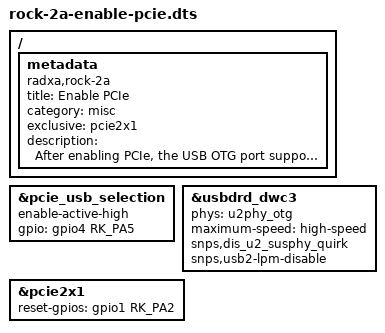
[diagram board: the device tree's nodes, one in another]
/dts-v1/;
/plugin/;

#include <dt-bindings/gpio/gpio.h>
#include <dt-bindings/pinctrl/rockchip.h>

/ {
	metadata {
		title = "Enable PCIe";
		compatible = "radxa,rock-2a";
		category = "misc";
		exclusive = "pcie2x1";
		description = "After enabling PCIe, the USB OTG port supports up to high speed";
	};
};

&pcie_usb_selection {
	enable-active-high;
	gpio = <&gpio4 RK_PA5 GPIO_ACTIVE_HIGH>;
};

&usbdrd_dwc3 {
	phys = <&u2phy_otg>;
	phy-names = "usb2-phy";
	maximum-speed = "high-speed";
	snps,dis_u2_susphy_quirk;
	snps,usb2-lpm-disable;
};

&pcie2x1 {
	reset-gpios = <&gpio1 RK_PA2 GPIO_ACTIVE_HIGH>;
	status = "okay";
};
